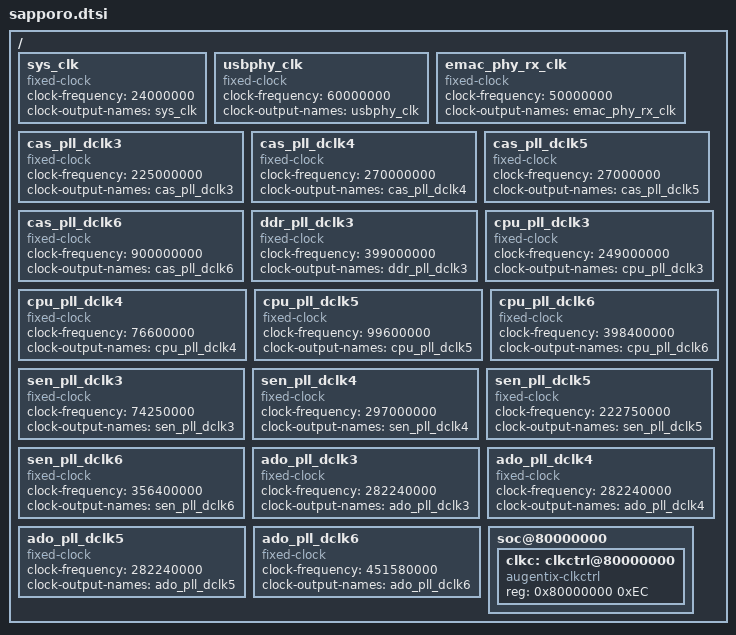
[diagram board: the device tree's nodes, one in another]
#include "../../../../../../top/include/generated/autoconf.h"
#include "sapporo-clk-enum.h"

/ {
	sys_clk: sys_clk {
		compatible = "fixed-clock";
		#clock-cells = <0>;
		clock-frequency = <24000000>;
		clock-output-names = "sys_clk";
	};

	usbphy_clk: usbphy_clk {
		compatible = "fixed-clock";
		#clock-cells = <0>;
		clock-frequency = <60000000>;
		clock-output-names = "usbphy_clk";
	};

	emac_phy_rx_clk: emac_phy_rx_clk {
		compatible = "fixed-clock";
		#clock-cells = <0>;
		clock-frequency = <50000000>;
		clock-output-names = "emac_phy_rx_clk";
	};

	cas_pll_dclk3: cas_pll_dclk3 {
		compatible = "fixed-clock";
		#clock-cells = <0>;
		clock-frequency = <225000000>;
		clock-output-names = "cas_pll_dclk3";
	};

	cas_pll_dclk4: cas_pll_dclk4 {
		compatible = "fixed-clock";
		#clock-cells = <0>;
		clock-frequency = <270000000>;
		clock-output-names = "cas_pll_dclk4";
	};

	cas_pll_dclk5: cas_pll_dclk5 {
		compatible = "fixed-clock";
		#clock-cells = <0>;
		clock-frequency = <27000000>;
		clock-output-names = "cas_pll_dclk5";
	};

	cas_pll_dclk6: cas_pll_dclk6 {
		compatible = "fixed-clock";
		#clock-cells = <0>;
		clock-frequency = <900000000>;
		clock-output-names = "cas_pll_dclk6";
	};

	ddr_pll_dclk3: ddr_pll_dclk3 {
		compatible = "fixed-clock";
		#clock-cells = <0>;
		clock-frequency = <399000000>;
		clock-output-names = "ddr_pll_dclk3";
	};

	cpu_pll_dclk3: cpu_pll_dclk3 {
		compatible = "fixed-clock";
		#clock-cells = <0>;
		clock-frequency = <249000000>;
		clock-output-names = "cpu_pll_dclk3";
	};

	cpu_pll_dclk4: cpu_pll_dclk4 {
		compatible = "fixed-clock";
		#clock-cells = <0>;
		clock-frequency = <76600000>;
		clock-output-names = "cpu_pll_dclk4";
	};

	cpu_pll_dclk5: cpu_pll_dclk5 {
		compatible = "fixed-clock";
		#clock-cells = <0>;
		clock-frequency = <99600000>;
		clock-output-names = "cpu_pll_dclk5";
	};

	cpu_pll_dclk6: cpu_pll_dclk6 {
		compatible = "fixed-clock";
		#clock-cells = <0>;
		clock-frequency = <398400000>;
		clock-output-names = "cpu_pll_dclk6";
	};

	sen_pll_dclk3: sen_pll_dclk3 {
		compatible = "fixed-clock";
		#clock-cells = <0>;
		clock-frequency = <74250000>;
		clock-output-names = "sen_pll_dclk3";
	};

	sen_pll_dclk4: sen_pll_dclk4 {
		compatible = "fixed-clock";
		#clock-cells = <0>;
		clock-frequency = <297000000>;
		clock-output-names = "sen_pll_dclk4";
	};

	sen_pll_dclk5: sen_pll_dclk5 {
		compatible = "fixed-clock";
		#clock-cells = <0>;
		clock-frequency = <222750000>;
		clock-output-names = "sen_pll_dclk5";
	};

	sen_pll_dclk6: sen_pll_dclk6 {
		compatible = "fixed-clock";
		#clock-cells = <0>;
		clock-frequency = <356400000>;
		clock-output-names = "sen_pll_dclk6";
	};

	ado_pll_dclk3: ado_pll_dclk3 {
		compatible = "fixed-clock";
		#clock-cells = <0>;
		clock-frequency = <282240000>;
		clock-output-names = "ado_pll_dclk3";
	};

	ado_pll_dclk4: ado_pll_dclk4 {
		compatible = "fixed-clock";
		#clock-cells = <0>;
		clock-frequency = <282240000>;
		clock-output-names = "ado_pll_dclk4";
	};

	ado_pll_dclk5: ado_pll_dclk5 {
		compatible = "fixed-clock";
		#clock-cells = <0>;
		clock-frequency = <282240000>;
		clock-output-names = "ado_pll_dclk5";
	};

	ado_pll_dclk6: ado_pll_dclk6 {
		compatible = "fixed-clock";
		#clock-cells = <0>;
		clock-frequency = <451580000>;
		clock-output-names = "ado_pll_dclk6";
	};

	soc@80000000 {
		clkc: clkctrl@80000000 {
			compatible = "augentix-clkctrl";
			reg = <0x80000000 0xEC>;
			#clock-cells = <1>;
			status = "okay";
		};
	};

};
